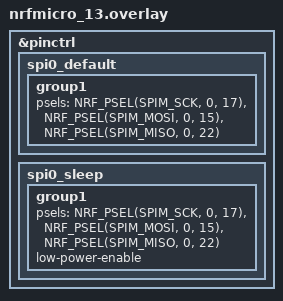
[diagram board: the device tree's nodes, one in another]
/*
 * Copyright (c) 2021 The ZMK Contributors
 *
 * SPDX-License-Identifier: MIT
 */
 &pinctrl {
    spi0_default: spi0_default {
		group1 {
			psels = <NRF_PSEL(SPIM_SCK, 0, 17)>,
					<NRF_PSEL(SPIM_MOSI, 0, 15)>,
					<NRF_PSEL(SPIM_MISO, 0, 22)>;
		};
	};
	spi0_sleep: spi0_sleep {
		group1 {
			psels = <NRF_PSEL(SPIM_SCK, 0, 17)>,
					<NRF_PSEL(SPIM_MOSI, 0, 15)>,
					<NRF_PSEL(SPIM_MISO, 0, 22)>;
			low-power-enable;
		};
	};
};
